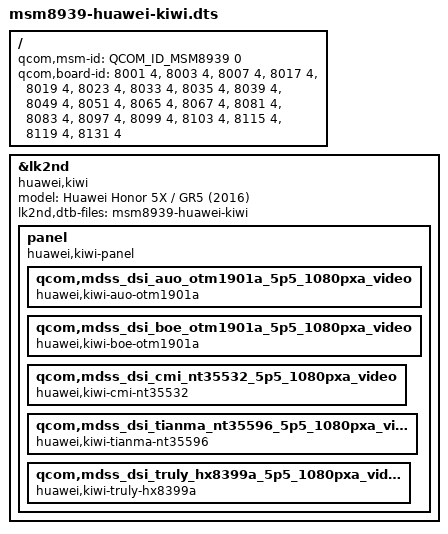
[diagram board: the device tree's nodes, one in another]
// SPDX-License-Identifier: BSD-3-Clause

#include <skeleton64.dtsi>
#include <lk2nd.dtsi>

/ {
	qcom,msm-id = <QCOM_ID_MSM8939 0>;
	qcom,board-id =
		<8001 4>, <8003 4>, <8007 4>, <8017 4>,
		<8019 4>, <8023 4>, <8033 4>, <8035 4>,
		<8039 4>, <8049 4>, <8051 4>, <8065 4>,
		<8067 4>, <8081 4>, <8083 4>, <8097 4>,
		<8099 4>, <8103 4>, <8115 4>, <8119 4>,
		<8131 4>;
};

&lk2nd {
	model = "Huawei Honor 5X / GR5 (2016)";
	compatible = "huawei,kiwi";

	lk2nd,dtb-files = "msm8939-huawei-kiwi";

	panel {
		compatible = "huawei,kiwi-panel", "lk2nd,panel";

		qcom,mdss_dsi_auo_otm1901a_5p5_1080pxa_video {
			compatible = "huawei,kiwi-auo-otm1901a";
		};
		qcom,mdss_dsi_boe_otm1901a_5p5_1080pxa_video {
			compatible = "huawei,kiwi-boe-otm1901a";
		};
		qcom,mdss_dsi_cmi_nt35532_5p5_1080pxa_video {
			compatible = "huawei,kiwi-cmi-nt35532";
		};
		qcom,mdss_dsi_tianma_nt35596_5p5_1080pxa_video {
			compatible = "huawei,kiwi-tianma-nt35596";
		};
		qcom,mdss_dsi_truly_hx8399a_5p5_1080pxa_video {
			compatible = "huawei,kiwi-truly-hx8399a";
		};
	};
};
